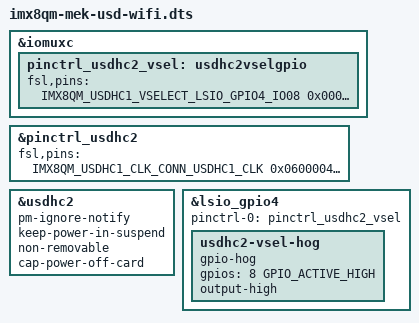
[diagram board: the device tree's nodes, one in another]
// SPDX-License-Identifier: (GPL-2.0 OR MIT)
/*
 * Copyright 2020 NXP
 */
#include "imx8qm-mek-rpmsg.dts"

&iomuxc {
	pinctrl_usdhc2_vsel: usdhc2vselgpio {
		fsl,pins = <
			IMX8QM_USDHC1_VSELECT_LSIO_GPIO4_IO08		0x00000021
		>;
	};
};

&pinctrl_usdhc2 {
	fsl,pins = <
		IMX8QM_USDHC1_CLK_CONN_USDHC1_CLK			0x06000041
		IMX8QM_USDHC1_CMD_CONN_USDHC1_CMD			0x00000021
		IMX8QM_USDHC1_DATA0_CONN_USDHC1_DATA0			0x00000021
		IMX8QM_USDHC1_DATA1_CONN_USDHC1_DATA1			0x00000021
		IMX8QM_USDHC1_DATA2_CONN_USDHC1_DATA2			0x00000021
		IMX8QM_USDHC1_DATA3_CONN_USDHC1_DATA3			0x00000021
	>;
};

&usdhc2 {
	/delete-property/ cd-gpios;
	/delete-property/ wp-gpios;
	pm-ignore-notify;
	keep-power-in-suspend;
	non-removable;
	cap-power-off-card;
};

&lsio_gpio4 {
	pinctrl-names = "default";
	pinctrl-0 = <&pinctrl_usdhc2_vsel>;

	usdhc2-vsel-hog {
		gpio-hog;
		gpios = <8 GPIO_ACTIVE_HIGH>;
		output-high;
	};
};
